# STM32WL3xx register map
File version: 1.0
Registers are 32-bit, read-write, reset 0x0 unless marked. A register's access mark holds for its fields unless they carry their own. Offsets are from the block's base; [hi:lo] are bit positions; {n}, {i} and the like mark numbered series; 'fields as' and 'values as' point back to an identical list.

## GPIOA — General-purpose I/Os (GPIO)
Base 0x48000000
Same registers: GPIOB 0x48100000
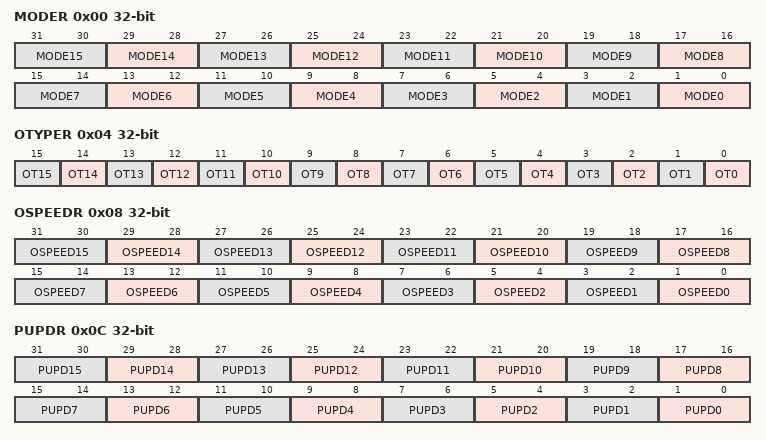
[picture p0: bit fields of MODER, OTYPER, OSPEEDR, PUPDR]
0x00 MODER — (@ 0x00000000) GPIO port mode register
  [2n+1:2n] MODE{n} (n=0..15)
0x04 OTYPER — (@ 0x00000004) GPIO port output type register
  [n] OT{n} (n=0..15)
0x08 OSPEEDR — (@ 0x00000008) GPIO port output speed register
  [2n+1:2n] OSPEED{n} (n=0..15)
0x0C PUPDR — (@ 0x0000000C) GPIO port pull-up/pull-down register
  [2n+1:2n] PUPD{n} (n=0..15)
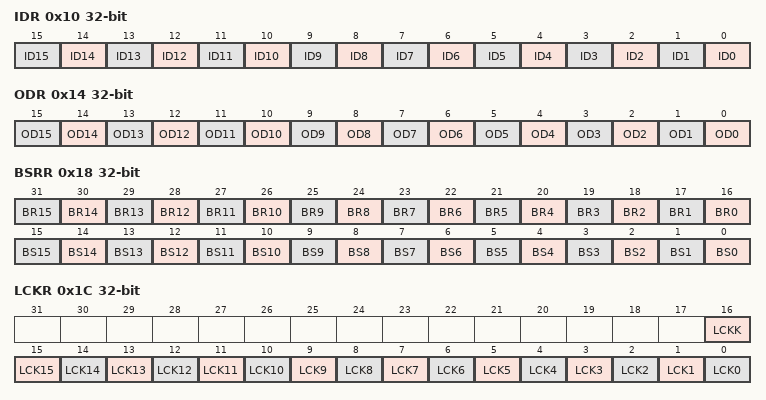
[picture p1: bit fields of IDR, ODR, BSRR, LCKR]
0x10 IDR — (@ 0x00000010) GPIO port input data register
  [n] ID{n} (n=0..15)
0x14 ODR — (@ 0x00000014) GPIO port output data register
  [n] OD{n} (n=0..15)
0x18 BSRR — (@ 0x00000018) GPIO port bit set/reset register
  [n+16] BR{n} (n=0..15), [n] BS{n} (n=0..15)
0x1C LCKR — (@ 0x0000001C) GPIO port configuration lock register
  [16] LCKK, [n] LCK{n} (n=0..15)
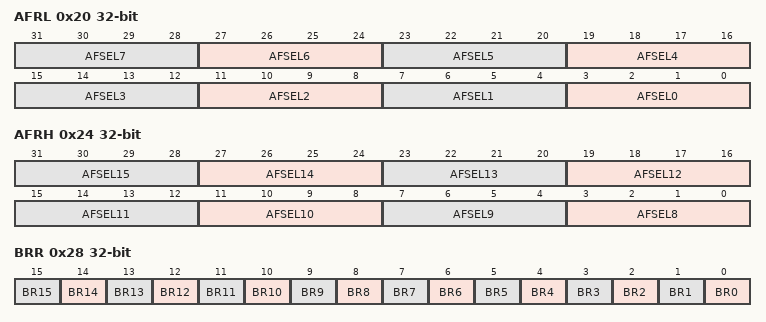
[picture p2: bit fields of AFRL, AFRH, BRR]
0x20 AFRL — (@ 0x00000020) GPIO alternate function register
  [4n+3:4n] AFSEL{n} (n=0..7)
0x24 AFRH — (@ 0x00000020) GPIO alternate function register
  [4n-29:4n-32] AFSEL{n} (n=8..15)
0x28 BRR — (@ 0x00000028) GPIO bit reset register
  [n] BR{n} (n=0..15)

## CRC — Cyclic redundancy check calculation unit (CRC)
Base 0x48200000
0x00 DR — (@ 0x00000000) Data register
0x04 IDR — (@ 0x00000004) Independent data register
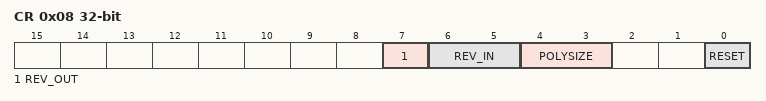
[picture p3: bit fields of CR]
0x08 CR — (@ 0x00000008) Control register
  [7] REV_OUT
    0=NONE (Output Data bit order not affected); 1=BIT (Output Data bit reversal done by bit)
  [6:5] REV_IN
    0=NONE (Input Data bit order not affected); 1=BYTE (Input Data bit reversal done by byte); 2=HALFWORD (Input Data bit reversal done by half-word); 3=WORD (Input Data bit reversal done by word)
  [4:3] POLYSIZE
    0=POLYLENGTH_32B (32 bits Polynomial size); 1=POLYLENGTH_16B (16 bits Polynomial size); 2=POLYLENGTH_8B (8 bits Polynomial size); 3=POLYLENGTH_7B (7 bits Polynomial size)
  [0] RESET
0x10 INIT — (@ 0x00000010) Initial CRC value
  [31:0] CRC_INIT
0x14 POL — (@ 0x00000014) Polynomial

## RNG — Random number generator (RNG)
Base 0x48600000
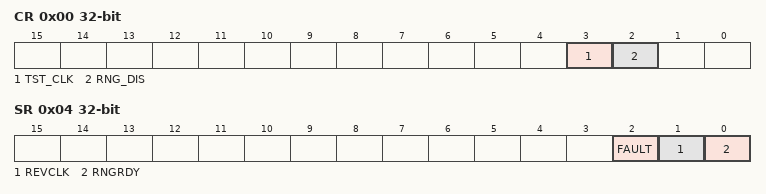
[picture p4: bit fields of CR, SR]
0x00 CR — (@ 0x00000000) Control register
  [3] TST_CLK, [2] RNG_DIS
0x04 SR — (@ 0x00000004) Status register
  [2] FAULT, [1] REVCLK, [0] RNGRDY
0x08 VAL — (@ 0x00000008) Data register
  [15:0] RANDOM_VALUE

## DMA1 — Direct memory access controller (DMA)
Base 0x48700000
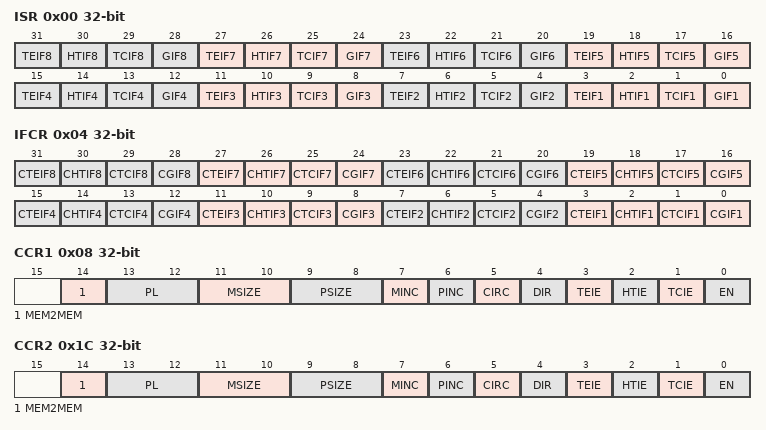
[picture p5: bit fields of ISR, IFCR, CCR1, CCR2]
0x00 ISR — (@ 0x00000000) Interrupt status register
  [4n-1] TEIF{n} (n=1..8), [4n-2] HTIF{n} (n=1..8), [4n-3] TCIF{n} (n=1..8), [4n-4] GIF{n} (n=1..8)
0x04 IFCR — (@ 0x00000004) Interrupt flag clear register
  [4n-1] CTEIF{n} (n=1..8), [4n-2] CHTIF{n} (n=1..8), [4n-3] CTCIF{n} (n=1..8), [4n-4] CGIF{n} (n=1..8)
0x08 CCR1 — DMA channel x configuration register
  [14] MEM2MEM, [13:12] PL, [11:10] MSIZE, [9:8] PSIZE, [7] MINC, [6] PINC, [5] CIRC, [4] DIR, [3] TEIE, [2] HTIE, [1] TCIE, [0] EN
0x0C CNDTR1 — DMA channel x number of data register
  [15:0] NDT
0x10 CPAR1 — DMA channel x peripheral address register
  [31:0] PA
{0x0+0x14*i} CMAR{i} (i=1..8) — DMA channel x memory address register
  [31:0] MA
0x1C CCR2 — DMA channel x configuration register
  fields as CCR1
0x20 CNDTR2 — DMA channel x number of data register
  [15:0] NDT
0x24 CPAR2 — DMA channel x peripheral address register
  [31:0] PA
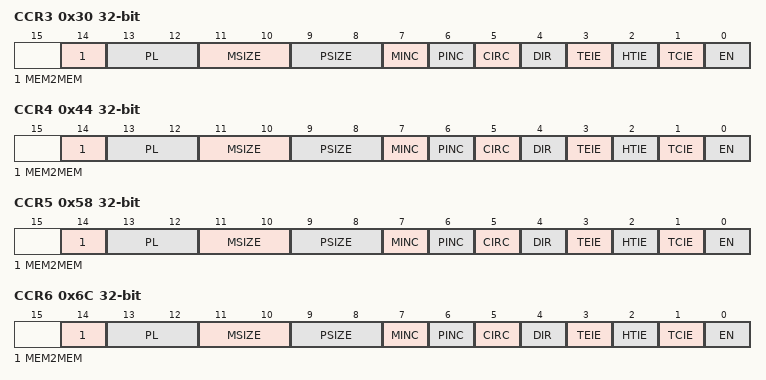
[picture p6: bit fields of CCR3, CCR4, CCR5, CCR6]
0x30 CCR3 — DMA channel x configuration register
  fields as CCR1
0x34 CNDTR3 — DMA channel x number of data register
  [15:0] NDT
0x38 CPAR3 — DMA channel x peripheral address register
  [31:0] PA
0x44 CCR4 — DMA channel x configuration register
  fields as CCR1
0x48 CNDTR4 — DMA channel x number of data register
  [15:0] NDT
0x4C CPAR4 — DMA channel x peripheral address register
  [31:0] PA
0x58 CCR5 — DMA channel x configuration register
  fields as CCR1
0x5C CNDTR5 — DMA channel x number of data register
  [15:0] NDT
0x60 CPAR5 — DMA channel x peripheral address register
  [31:0] PA
0x6C CCR6 — DMA channel x configuration register
  fields as CCR1
0x70 CNDTR6 — DMA channel x number of data register
  [15:0] NDT
0x74 CPAR6 — DMA channel x peripheral address register
  [31:0] PA
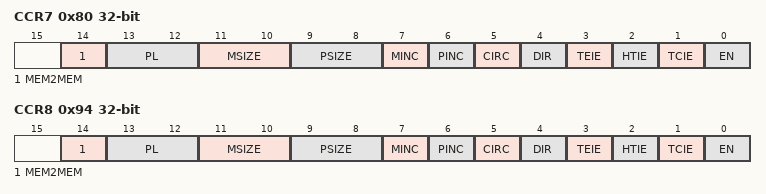
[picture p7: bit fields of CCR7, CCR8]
0x80 CCR7 — DMA channel x configuration register
  fields as CCR1
0x84 CNDTR7 — DMA channel x number of data register
  [15:0] NDT
0x88 CPAR7 — DMA channel x peripheral address register
  [31:0] PA
0x94 CCR8 — DMA channel x configuration register
  fields as CCR1
0x98 CNDTR8 — DMA channel x number of data register
  [15:0] NDT
0x9C CPAR8 — DMA channel x peripheral address register
  [31:0] PA
